AUTOSAR XML (schema 4-0-3)
standard types defined: Boolean, UInt8
package /AUTOSAR_Platform/DataConstrs
  range DC_Boolean: raw 0..1
package /DataTypes/Units
  unit NoUnit1: display-name=NoUnit, factor-si-to-unit=1, offset-si-to-unit=0
package /PATAC/MSM/ComponentTypes
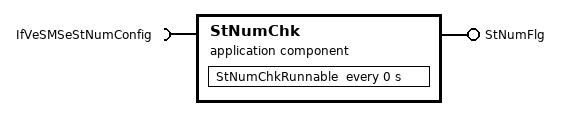
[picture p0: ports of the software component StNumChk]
  application sw component type StNumChk
    provide port StNumFlg: provided-interface=StNumFlg
      provided-com-specs:
        data-element=Is4s, init-value=0
        data-element=Is6s, init-value=0
        data-element=Is6s7s, init-value=0
        data-element=Is7s, init-value=0
    require port IfVeSMSeStNumConfig: nonqueued-receiver-com-spec{data-element=Val, filter=data-filter-type=ALWAYS, init-value=0}, required-interface=IfVeSMSeStNumConfig
    behavior StNumChk_InternalBehavior
      timing event Runnable_InitEvent: start-on-event=StNumChkRunnable, period=0
      runnable StNumChkRunnable
        data-receive-point-by-arguments:
          access REC_IfVeSMSeStNumConfig_Val: accessed-variable=IfVeSMSeStNumConfig.Val
        data-send-points:
          4 x access:
            SEND_StNumFlg_Is4s: accessed-variable=StNumFlg.Is4s
            SEND_StNumFlg_Is6s: accessed-variable=StNumFlg.Is6s
            SEND_StNumFlg_Is6s7s: accessed-variable=StNumFlg.Is6s7s
            SEND_StNumFlg_Is7s: accessed-variable=StNumFlg.Is7s
  swc implementation StNumChk_Implementation: behavior=StNumChk_InternalBehavior
    code-descriptors:
      code Default: artifact-descriptors=autosar-engineering-object={short-label=Default, category=SWSRC}
package /PATAC/MSM/DataTypes/ImplementationDataTypes
  impl type IfVeSMSeStNumConfig: category=VALUE, base-type=UInt8, sw-calibration-access=READ-ONLY, compu {0=SeatNum4Config, 1=SeatNum6Config, 2=SeatNum7Config, 3=SeatNum4PConfig}, type-emitter=RTE
package /PATAC/MSM/ModeAdjust/PortInterface
  sender receiver interface IfVeSMSeStNumConfig: invalidation-policy{data-element=Val, handle-invalid=DONT-INVALIDATE}
    data Val: type=IfVeSMSeStNumConfig
  sender receiver interface StNumFlg
    4 x data, all with type=Boolean:
      Is4s
      Is6s
      Is6s7s
      Is7s
    invalidation-policys:
      data-element=Is7s, handle-invalid=DONT-INVALIDATE
      data-element=Is6s, handle-invalid=DONT-INVALIDATE
      data-element=Is4s, handle-invalid=DONT-INVALIDATE
      data-element=Is6s7s, handle-invalid=DONT-INVALIDATE
